# M480_v1 register map
File version: 1.0
Registers are 32-bit, read-write, reset 0x0 unless marked. A register's access mark holds for its fields unless they carry their own. Offsets are from the block's base; [hi:lo] are bit positions; 'fields as' and 'values as' point back to an identical list.

## NMI — NMI Register Map
Base 0x40000300
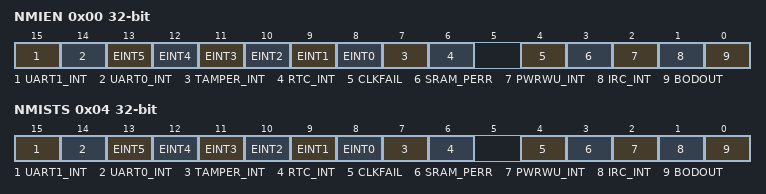
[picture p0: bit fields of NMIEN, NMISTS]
0x00 NMIEN — NMI Source Interrupt Enable Register
  [15] UART1_INT — UART1 NMI Source Enable (Write Protect). Note: This bit is write protected. Refer to the SYS_REGLCTL register.
    0=UART1 NMI source Disabled; 1=UART1 NMI source Enabled
  [14] UART0_INT — UART0 NMI Source Enable (Write Protect). Note: This bit is write protected. Refer to the SYS_REGLCTL register.
    0=UART0 NMI source Disabled; 1=UART0 NMI source Enabled
  [13] EINT5 — External Interrupt From PF.0 Pin NMI Source Enable (Write Protect). Note: This bit is write protected. Refer to the SYS_REGLCTL register.
    0=External interrupt from PF.0 pin NMI source Disabled; 1=External interrupt from PF.0 pin NMI source Enabled
  [12] EINT4 — External Interrupt From PE.0 Pin NMI Source Enable (Write Protect). Note: This bit is write protected. Refer to the SYS_REGLCTL register.
    0=External interrupt from PE.0 pin NMI source Disabled; 1=External interrupt from PE.0 pin NMI source Enabled
  [11] EINT3 — External Interrupt From PD.0 Pin NMI Source Enable (Write Protect). Note: This bit is write protected. Refer to the SYS_REGLCTL register.
    0=External interrupt from PD.0 pin NMI source Disabled; 1=External interrupt from PD.0 pin NMI source Enabled
  [10] EINT2 — External Interrupt From PC.0 Pin NMI Source Enable (Write Protect). Note: This bit is write protected. Refer to the SYS_REGLCTL register.
    0=External interrupt from PC.0 pin NMI source Disabled; 1=External interrupt from PC.0 pin NMI source Enabled
  [9] EINT1 — External Interrupt From PB.0, PD.3 or PE.5 Pin NMI Source Enable (Write Protect). Note: This bit is write protected. Refer to the SYS_REGLCTL register.
    0=External interrupt from PB.0, PD.3 or PE.5 pin NMI source Disabled; 1=External interrupt from PB.0, PD.3 or PE.5 pin NMI source Enabled
  [8] EINT0 — External Interrupt From PA.0, PD.2 or PE.4 Pin NMI Source Enable (Write Protect). Note: This bit is write protected. Refer to the SYS_REGLCTL register.
    0=External interrupt from PA.0, PD.2 or PE.4 pin NMI source Disabled; 1=External interrupt from PA.0, PD.2 or PE.4 pin NMI source Enabled
  [7] TAMPER_INT — TAMPER_INT NMI Source Enable (Write Protect). Note: This bit is write protected. Refer to the SYS_REGLCTL register.
    0=Backup register tamper detected interrupt.NMI source Disabled; 1=Backup register tamper detected interrupt.NMI source Enabled
  [6] RTC_INT — RTC NMI Source Enable (Write Protect). Note: This bit is write protected. Refer to the SYS_REGLCTL register.
    0=RTC NMI source Disabled; 1=RTC NMI source Enabled
  [4] CLKFAIL — Clock Fail Detected NMI Source Enable (Write Protect). Note: This bit is write protected. Refer to the SYS_REGLCTL register.
    0=Clock fail detected interrupt NMI source Disabled; 1=Clock fail detected interrupt NMI source Enabled
  [3] SRAM_PERR — SRAM ParityCheck Error NMI Source Enable (Write Protect). Note: This bit is write protected. Refer to the SYS_REGLCTL register.
    0=SRAM parity check error NMI source Disabled; 1=SRAM parity check error NMI source Enabled
  [2] PWRWU_INT — Power-down Mode Wake-up NMI Source Enable (Write Protect). Note: This bit is write protected. Refer to the SYS_REGLCTL register.
    0=Power-down mode wake-up NMI source Disabled; 1=Power-down mode wake-up NMI source Enabled
  [1] IRC_INT — IRC TRIM NMI Source Enable (Write Protect). Note: This bit is write protected. Refer to the SYS_REGLCTL register.
    0=IRC TRIM NMI source Disabled; 1=IRC TRIM NMI source Enabled
  [0] BODOUT — BOD NMI Source Enable (Write Protect). Note: This bit is write protected. Refer to the SYS_REGLCTL register.
    0=BOD NMI source Disabled; 1=BOD NMI source Enabled
0x04 NMISTS ro — NMI Source Interrupt Status Register
  [15] UART1_INT — UART1 Interrupt Flag (Read Only)
    0=UART1 interrupt is deasserted; 1=UART1 interrupt is asserted
  [14] UART0_INT — UART0 Interrupt Flag (Read Only)
    values as UART1_INT
  [13] EINT5 — External Interrupt From PF.0 Pin Interrupt Flag (Read Only)
    0=External Interrupt from PF.0 interrupt is deasserted; 1=External Interrupt from PF.0 interrupt is asserted
  [12] EINT4 — External Interrupt From PE.0 Pin Interrupt Flag (Read Only)
    0=External Interrupt from PE.0 interrupt is deasserted; 1=External Interrupt from PE.0 interrupt is asserted
  [11] EINT3 — External Interrupt From PD.0 Pin Interrupt Flag (Read Only)
    0=External Interrupt from PD.0 interrupt is deasserted; 1=External Interrupt from PD.0 interrupt is asserted
  [10] EINT2 — External Interrupt From PC.0 Pin Interrupt Flag (Read Only)
    0=External Interrupt from PC.0 interrupt is deasserted; 1=External Interrupt from PC.0 interrupt is asserted
  [9] EINT1 — External Interrupt From PB.0, PD.3 or PE.5 Pin Interrupt Flag (Read Only)
    0=External Interrupt from PB.0, PD.3 or PE.5 interrupt is deasserted; 1=External Interrupt from PB.0, PD.3 or PE.5 interrupt is asserted
  [8] EINT0 — External Interrupt From PA.0, PD.2 or PE.4 Pin Interrupt Flag (Read Only)
    0=External Interrupt from PA.0, PD.2 or PE.4 interrupt is deasserted; 1=External Interrupt from PA.0, PD.2 or PE.4 interrupt is asserted
  [7] TAMPER_INT — TAMPER_INT Interrupt Flag (Read Only)
    0=Backup register tamper detected interrupt is deasserted; 1=Backup register tamper detected interrupt is asserted
  [6] RTC_INT — RTC Interrupt Flag (Read Only)
    0=RTC interrupt is deasserted; 1=RTC interrupt is asserted
  [4] CLKFAIL — Clock Fail Detected Interrupt Flag (Read Only)
    0=Clock fail detected interrupt is deasserted; 1=Clock fail detected interrupt is asserted
  [3] SRAM_PERR — SRAM ParityCheck Error Interrupt Flag (Read Only)
    0=SRAM parity check error interrupt is deasserted; 1=SRAM parity check error interrupt is asserted
  [2] PWRWU_INT — Power-down Mode Wake-up Interrupt Flag (Read Only)
    0=Power-down mode wake-up interrupt is deasserted; 1=Power-down mode wake-up interrupt is asserted
  [1] IRC_INT — IRC TRIM Interrupt Flag (Read Only)
    0=HIRC TRIM interrupt is deasserted; 1=HIRC TRIM interrupt is asserted
  [0] BODOUT — BOD Interrupt Flag (Read Only)
    0=BOD interrupt is deasserted; 1=BOD interrupt is asserted
